# ioam3358 register map
Registers are 32-bit, access not given, no defined reset value unless marked. A register's access mark holds for its fields unless they carry their own. Addresses are absolute; registers are grouped by the start of their names; [hi:lo] are bit positions; {n}, {i} and the like mark numbered series; 'fields as' and 'values as' point back to an identical list.

## EDMATC1
0x49900000 EDMATC1_PID
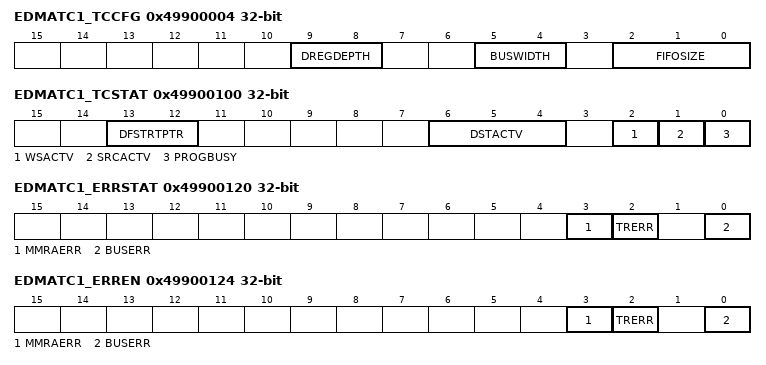
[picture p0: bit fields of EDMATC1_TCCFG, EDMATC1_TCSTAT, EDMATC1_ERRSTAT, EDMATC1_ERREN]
0x49900004 EDMATC1_TCCFG
  [9:8] DREGDEPTH, [5:4] BUSWIDTH, [2:0] FIFOSIZE
0x49900100 EDMATC1_TCSTAT
  [13:12] DFSTRTPTR, [6:4] DSTACTV, [2] WSACTV, [1] SRCACTV, [0] PROGBUSY
0x49900120 EDMATC1_ERRSTAT
  [3] MMRAERR, [2] TRERR, [0] BUSERR
0x49900124 EDMATC1_ERREN
  [3] MMRAERR, [2] TRERR, [0] BUSERR
0x49900128 EDMATC1_ERRCLR
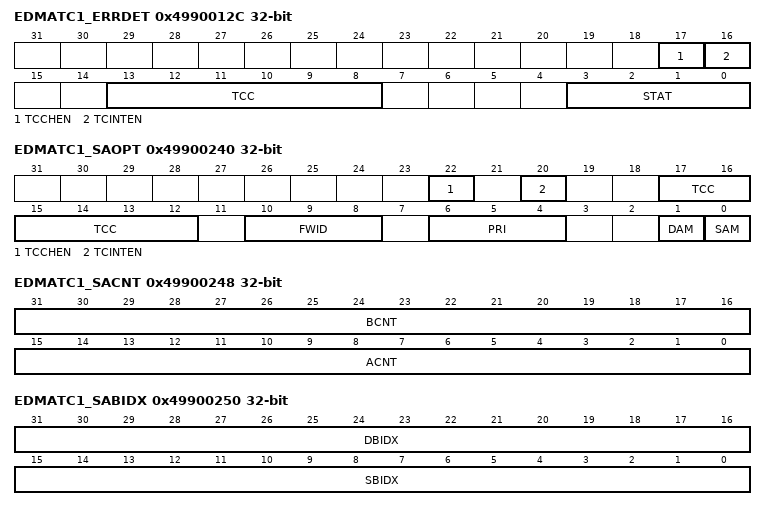
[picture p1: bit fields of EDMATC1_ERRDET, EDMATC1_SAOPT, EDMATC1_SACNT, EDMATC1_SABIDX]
0x4990012C EDMATC1_ERRDET
  [17] TCCHEN, [16] TCINTEN, [13:8] TCC, [3:0] STAT
0x49900130 EDMATC1_ERRCMD
0x49900140 EDMATC1_RDRATE
  [2:0] RDRATE
0x49900240 EDMATC1_SAOPT
  [22] TCCHEN, [20] TCINTEN, [17:12] TCC, [10:8] FWID, [6:4] PRI, [1] DAM, [0] SAM
0x49900244 EDMATC1_SASRC
0x49900248 EDMATC1_SACNT
  [31:16] BCNT, [15:0] ACNT
0x49900250 EDMATC1_SABIDX
  [31:16] DBIDX, [15:0] SBIDX
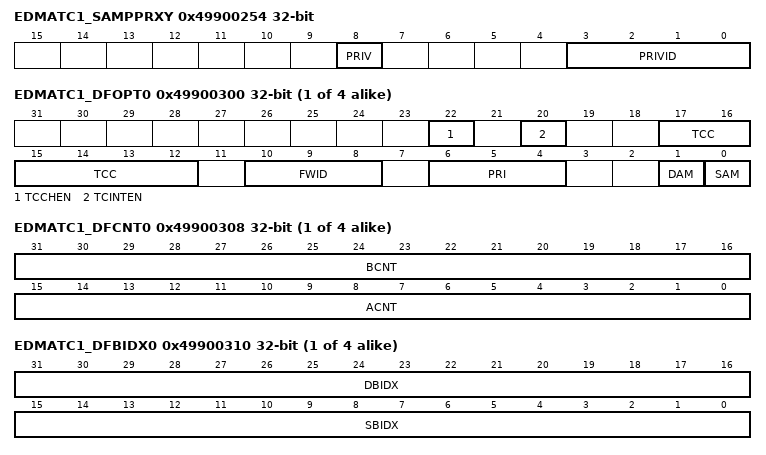
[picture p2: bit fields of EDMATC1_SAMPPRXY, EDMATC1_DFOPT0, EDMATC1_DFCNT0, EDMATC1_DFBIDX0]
0x49900254 EDMATC1_SAMPPRXY
  [8] PRIV, [3:0] PRIVID
0x49900258 EDMATC1_SACNTRLD
  [15:0] ACNTRLD
0x4990025C EDMATC1_SASRCBREF
0x49900280 EDMATC1_DFCNTRLD
  [15:0] ACNTRLD
0x49900288 EDMATC1_DFDSTBREF
{0x49900300+0x40*i} EDMATC1_DFOPT{i} (i=0..3)
  fields as EDMATC1_SAOPT
{0x49900308+0x40*i} EDMATC1_DFCNT{i} (i=0..3)
  [31:16] BCNT, [15:0] ACNT
{0x4990030C+0x40*i} EDMATC1_DFDST{i} (i=0..3)
{0x49900310+0x40*i} EDMATC1_DFBIDX{i} (i=0..3)
  [31:16] DBIDX, [15:0] SBIDX
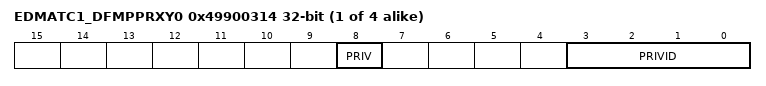
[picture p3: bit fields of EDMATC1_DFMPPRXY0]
{0x49900314+0x40*i} EDMATC1_DFMPPRXY{i} (i=0..3)
  [8] PRIV, [3:0] PRIVID

## EDMATC2
0x49A00000 EDMATC2_PID
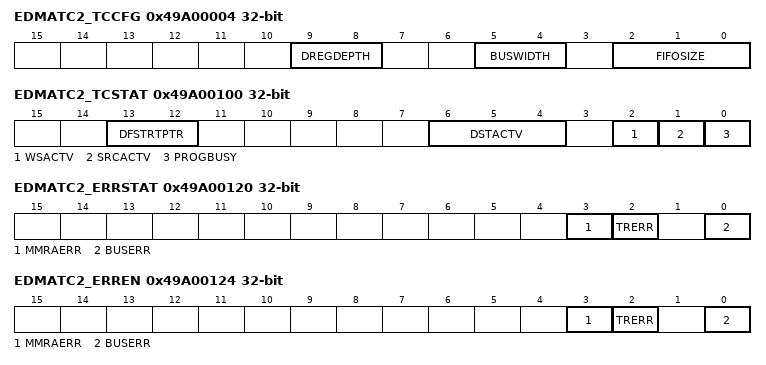
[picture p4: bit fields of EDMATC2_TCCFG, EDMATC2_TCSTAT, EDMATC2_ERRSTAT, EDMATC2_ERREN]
0x49A00004 EDMATC2_TCCFG
  [9:8] DREGDEPTH, [5:4] BUSWIDTH, [2:0] FIFOSIZE
0x49A00100 EDMATC2_TCSTAT
  [13:12] DFSTRTPTR, [6:4] DSTACTV, [2] WSACTV, [1] SRCACTV, [0] PROGBUSY
0x49A00120 EDMATC2_ERRSTAT
  [3] MMRAERR, [2] TRERR, [0] BUSERR
0x49A00124 EDMATC2_ERREN
  [3] MMRAERR, [2] TRERR, [0] BUSERR
0x49A00128 EDMATC2_ERRCLR
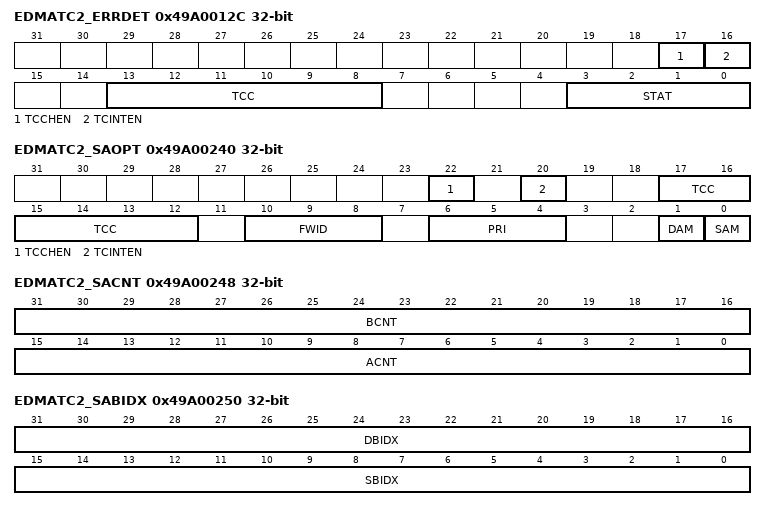
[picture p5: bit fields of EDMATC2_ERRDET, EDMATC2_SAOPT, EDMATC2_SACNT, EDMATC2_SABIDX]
0x49A0012C EDMATC2_ERRDET
  [17] TCCHEN, [16] TCINTEN, [13:8] TCC, [3:0] STAT
0x49A00130 EDMATC2_ERRCMD
0x49A00140 EDMATC2_RDRATE
  [2:0] RDRATE
0x49A00240 EDMATC2_SAOPT
  [22] TCCHEN, [20] TCINTEN, [17:12] TCC, [10:8] FWID, [6:4] PRI, [1] DAM, [0] SAM
0x49A00244 EDMATC2_SASRC
0x49A00248 EDMATC2_SACNT
  [31:16] BCNT, [15:0] ACNT
0x49A00250 EDMATC2_SABIDX
  [31:16] DBIDX, [15:0] SBIDX
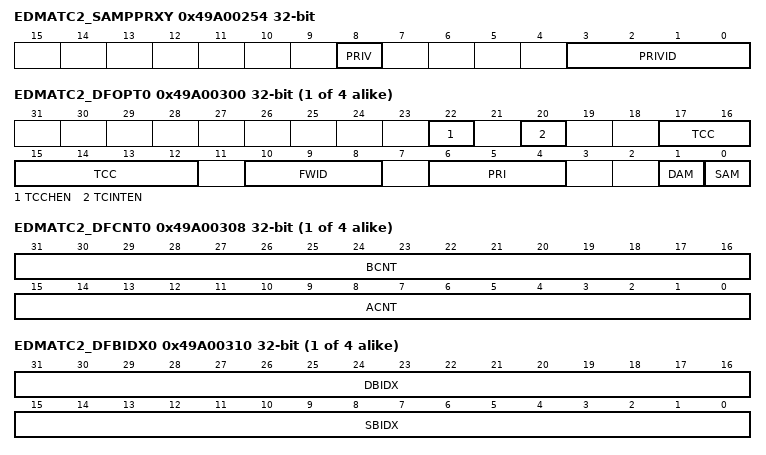
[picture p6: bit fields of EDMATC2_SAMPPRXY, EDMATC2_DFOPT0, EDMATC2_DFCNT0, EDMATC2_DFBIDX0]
0x49A00254 EDMATC2_SAMPPRXY
  [8] PRIV, [3:0] PRIVID
0x49A00258 EDMATC2_SACNTRLD
  [15:0] ACNTRLD
0x49A0025C EDMATC2_SASRCBREF
0x49A00280 EDMATC2_DFCNTRLD
  [15:0] ACNTRLD
0x49A00288 EDMATC2_DFDSTBREF
{0x49A00300+0x40*i} EDMATC2_DFOPT{i} (i=0..3)
  fields as EDMATC2_SAOPT
{0x49A00308+0x40*i} EDMATC2_DFCNT{i} (i=0..3)
  [31:16] BCNT, [15:0] ACNT
{0x49A0030C+0x40*i} EDMATC2_DFDST{i} (i=0..3)
{0x49A00310+0x40*i} EDMATC2_DFBIDX{i} (i=0..3)
  [31:16] DBIDX, [15:0] SBIDX
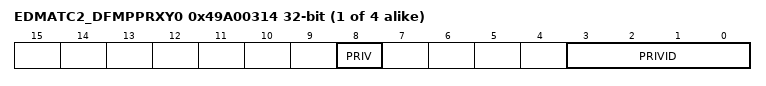
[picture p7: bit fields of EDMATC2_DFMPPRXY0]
{0x49A00314+0x40*i} EDMATC2_DFMPPRXY{i} (i=0..3)
  [8] PRIV, [3:0] PRIVID

## TSC
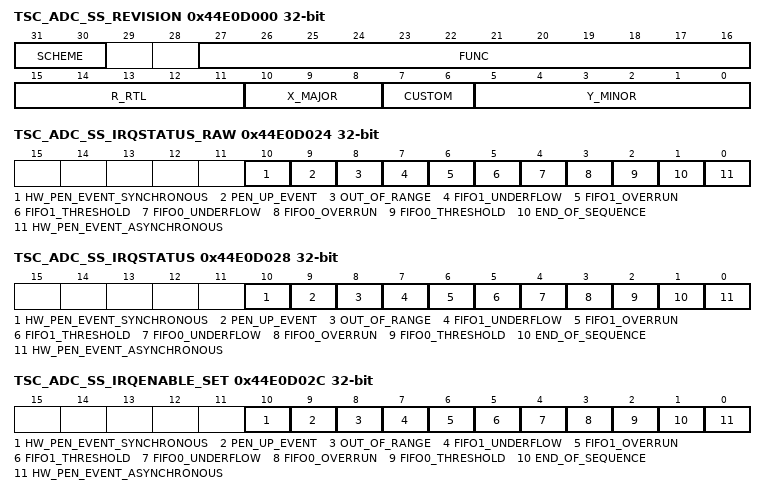
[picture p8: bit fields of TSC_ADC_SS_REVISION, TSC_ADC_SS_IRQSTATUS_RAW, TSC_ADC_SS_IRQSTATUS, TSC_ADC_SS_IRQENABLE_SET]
0x44E0D000 TSC_ADC_SS_REVISION
  [31:30] SCHEME, [27:16] FUNC, [15:11] R_RTL, [10:8] X_MAJOR, [7:6] CUSTOM, [5:0] Y_MINOR
0x44E0D010 TSC_ADC_SS_SYSCONFIG
  [3:2] IDLEMODE
0x44E0D020 TSC_ADC_SS_IRQ_EOI
  [0] LINE_NUMBER
0x44E0D024 TSC_ADC_SS_IRQSTATUS_RAW
  [10] HW_PEN_EVENT_SYNCHRONOUS, [9] PEN_UP_EVENT, [8] OUT_OF_RANGE, [7] FIFO1_UNDERFLOW, [6] FIFO1_OVERRUN, [5] FIFO1_THRESHOLD, [4] FIFO0_UNDERFLOW, [3] FIFO0_OVERRUN, [2] FIFO0_THRESHOLD, [1] END_OF_SEQUENCE, [0] HW_PEN_EVENT_ASYNCHRONOUS
0x44E0D028 TSC_ADC_SS_IRQSTATUS
  fields as TSC_ADC_SS_IRQSTATUS_RAW
0x44E0D02C TSC_ADC_SS_IRQENABLE_SET
  fields as TSC_ADC_SS_IRQSTATUS_RAW
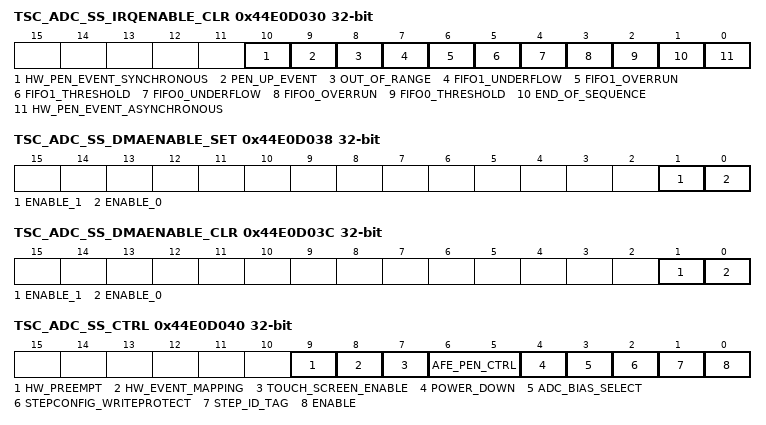
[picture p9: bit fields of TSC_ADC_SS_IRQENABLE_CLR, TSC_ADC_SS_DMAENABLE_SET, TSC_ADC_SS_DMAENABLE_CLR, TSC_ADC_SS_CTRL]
0x44E0D030 TSC_ADC_SS_IRQENABLE_CLR
  fields as TSC_ADC_SS_IRQSTATUS_RAW
0x44E0D034 TSC_ADC_SS_IRQWAKEUP
  [0] WAKEEN0
0x44E0D038 TSC_ADC_SS_DMAENABLE_SET
  [1] ENABLE_1, [0] ENABLE_0
0x44E0D03C TSC_ADC_SS_DMAENABLE_CLR
  [1] ENABLE_1, [0] ENABLE_0
0x44E0D040 TSC_ADC_SS_CTRL
  [9] HW_PREEMPT, [8] HW_EVENT_MAPPING, [7] TOUCH_SCREEN_ENABLE, [6:5] AFE_PEN_CTRL, [4] POWER_DOWN, [3] ADC_BIAS_SELECT, [2] STEPCONFIG_WRITEPROTECT, [1] STEP_ID_TAG, [0] ENABLE
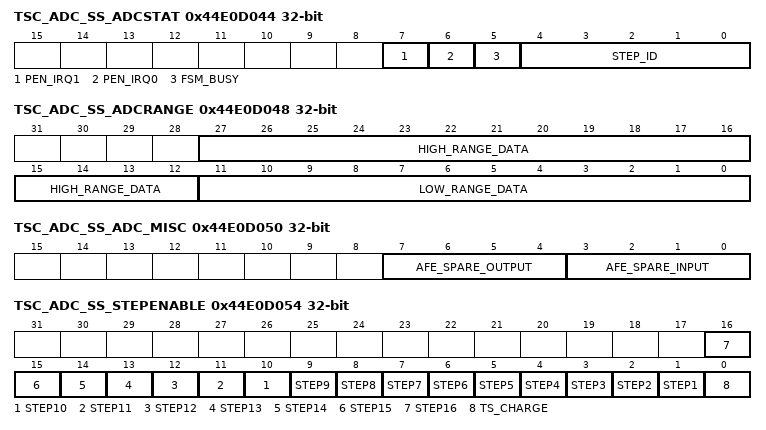
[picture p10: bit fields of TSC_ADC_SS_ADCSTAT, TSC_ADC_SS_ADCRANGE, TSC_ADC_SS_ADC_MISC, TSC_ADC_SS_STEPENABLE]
0x44E0D044 TSC_ADC_SS_ADCSTAT
  [7] PEN_IRQ1, [6] PEN_IRQ0, [5] FSM_BUSY, [4:0] STEP_ID
0x44E0D048 TSC_ADC_SS_ADCRANGE
  [27:12] HIGH_RANGE_DATA, [11:0] LOW_RANGE_DATA
0x44E0D04C TSC_ADC_SS_ADC_CLKDIV
  [15:0] ADC_CLKDIV
0x44E0D050 TSC_ADC_SS_ADC_MISC
  [7:4] AFE_SPARE_OUTPUT, [3:0] AFE_SPARE_INPUT
0x44E0D054 TSC_ADC_SS_STEPENABLE
  [n] STEP{n} (n=1..16), [0] TS_CHARGE
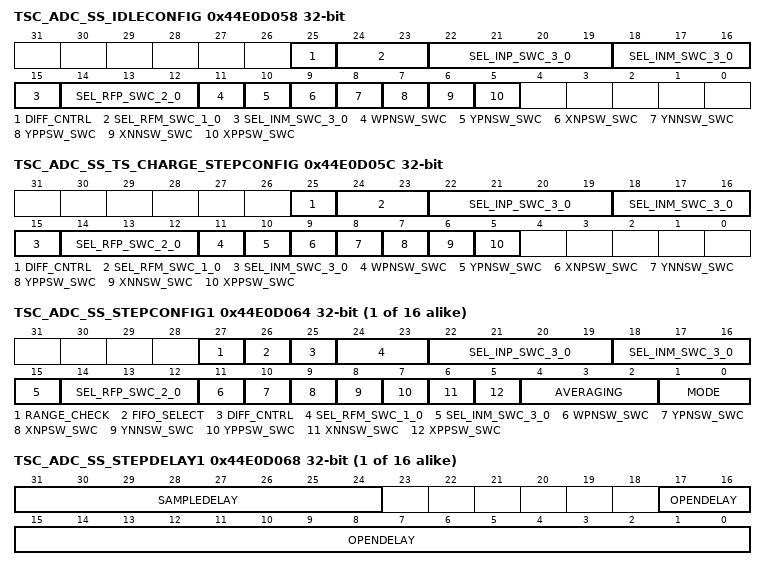
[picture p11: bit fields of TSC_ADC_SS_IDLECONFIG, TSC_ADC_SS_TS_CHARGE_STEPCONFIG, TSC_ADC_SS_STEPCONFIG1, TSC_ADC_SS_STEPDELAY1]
0x44E0D058 TSC_ADC_SS_IDLECONFIG
  [25] DIFF_CNTRL, [24:23] SEL_RFM_SWC_1_0, [22:19] SEL_INP_SWC_3_0, [18:15] SEL_INM_SWC_3_0, [14:12] SEL_RFP_SWC_2_0, [11] WPNSW_SWC, [10] YPNSW_SWC, [9] XNPSW_SWC, [8] YNNSW_SWC, [7] YPPSW_SWC, [6] XNNSW_SWC, [5] XPPSW_SWC
0x44E0D05C TSC_ADC_SS_TS_CHARGE_STEPCONFIG
  fields as TSC_ADC_SS_IDLECONFIG
0x44E0D060 TSC_ADC_SS_TS_CHARGE_DELAY
  [17:0] OPENDELAY
{0x44E0D05C+8i} TSC_ADC_SS_STEPCONFIG{i} (i=1..16)
  [27] RANGE_CHECK, [26] FIFO_SELECT, [25] DIFF_CNTRL, [24:23] SEL_RFM_SWC_1_0, [22:19] SEL_INP_SWC_3_0, [18:15] SEL_INM_SWC_3_0, [14:12] SEL_RFP_SWC_2_0, [11] WPNSW_SWC, [10] YPNSW_SWC, [9] XNPSW_SWC, [8] YNNSW_SWC, [7] YPPSW_SWC, [6] XNNSW_SWC, [5] XPPSW_SWC, [4:2] AVERAGING, [1:0] MODE
{0x44E0D060+8i} TSC_ADC_SS_STEPDELAY{i} (i=1..16)
  [31:24] SAMPLEDELAY, [17:0] OPENDELAY
0x44E0D0E4 TSC_ADC_SS_FIFO0COUNT
  [6:0] WORDS_IN_FIFO
0x44E0D0E8 TSC_ADC_SS_FIFO0THRESHOLD
  [5:0] FIFO_THRESHOLD_LEVEL
0x44E0D0EC TSC_ADC_SS_DMA0REQ
  [5:0] DMA_REQUEST_LEVEL
0x44E0D0F0 TSC_ADC_SS_FIFO1COUNT
  [6:0] WORDS_IN_FIFO
0x44E0D0F4 TSC_ADC_SS_FIFO1THRESHOLD
  [5:0] FIFO_THRESHOLD_LEVEL
0x44E0D0F8 TSC_ADC_SS_DMA1REQ
  [5:0] DMA_REQUEST_LEVEL
